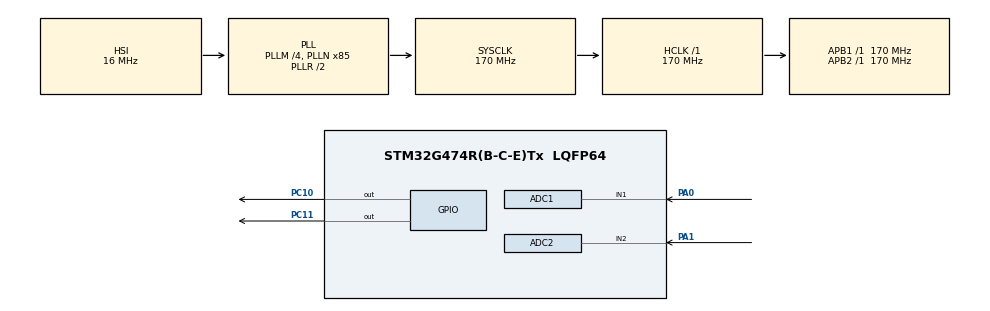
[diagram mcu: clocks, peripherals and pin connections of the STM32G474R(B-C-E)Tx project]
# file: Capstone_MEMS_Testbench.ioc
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ADC1.Channel-3\#ChannelRegularConversion=ADC_CHANNEL_1
ADC1.DMAAccessModeView=ENABLE
ADC1.DMAContinuousRequests=ENABLE
ADC1.ExternalTrigConv=ADC_EXTERNALTRIG_T6_TRGO
ADC1.Mode=ADC_DUALMODE_REGSIMULT
ADC1.NbrOfConversionFlag=1
ADC1.OffsetNumber-3\#ChannelRegularConversion=ADC_OFFSET_NONE
ADC1.Rank-3\#ChannelRegularConversion=1
ADC1.SamplingTime-3\#ChannelRegularConversion=ADC_SAMPLETIME_12CYCLES_5
ADC1.master=1
ADC2.Channel-0\#ChannelRegularConversion=ADC_CHANNEL_2
ADC2.DMAAccessModeView=ENABLE
ADC2.Mode=ADC_DUALMODE_REGSIMULT
ADC2.NbrOfConversionFlag=1
ADC2.OffsetNumber-0\#ChannelRegularConversion=ADC_OFFSET_NONE
ADC2.Rank-0\#ChannelRegularConversion=1
ADC2.SamplingTime-0\#ChannelRegularConversion=ADC_SAMPLETIME_12CYCLES_5
Dma.ADC1.0.Direction=DMA_PERIPH_TO_MEMORY
Dma.ADC1.0.EventEnable=DISABLE
Dma.ADC1.0.Instance=DMA1_Channel1
Dma.ADC1.0.MemDataAlignment=DMA_MDATAALIGN_WORD
Dma.ADC1.0.MemInc=DMA_MINC_ENABLE
Dma.ADC1.0.Mode=DMA_CIRCULAR
Dma.ADC1.0.PeriphDataAlignment=DMA_PDATAALIGN_WORD
Dma.ADC1.0.PeriphInc=DMA_PINC_DISABLE
Dma.ADC1.0.Polarity=HAL_DMAMUX_REQ_GEN_RISING
Dma.ADC1.0.Priority=DMA_PRIORITY_VERY_HIGH
Dma.ADC1.0.RequestNumber=1
Dma.ADC1.0.SignalID=NONE
Dma.ADC1.0.SyncEnable=DISABLE
Dma.ADC1.0.SyncPolarity=HAL_DMAMUX_SYNC_NO_EVENT
Dma.ADC1.0.SyncRequestNumber=1
Dma.ADC1.0.SyncSignalID=NONE
Dma.Request0=ADC1
Mcu.Family=STM32G4
Mcu.Name=STM32G474R(B-C-E)Tx
Mcu.Package=LQFP64
NUCLEO-G474RE.BUTTON=1
NUCLEO-G474RE.Bsp_Common_DEMO=true
NUCLEO-G474RE.LD2=true
NUCLEO-G474RE.VCP=true
NVIC.DMA1_Channel1_IRQn=true\:0\:0\:false\:false\:true\:false\:true\:true
NVIC.EXTI15_10_IRQn=true\:0\:0\:false\:false\:true\:false\:true\:true
NVIC.PriorityGroup=NVIC_PRIORITYGROUP_4
PA0.Mode=IN1-Single-Ended
PA0.Signal=ADC1_IN1
PA1.Mode=IN2-Single-Ended
PA1.Signal=ADC2_IN2
PA13.GPIO_Label=T_SWDIO
PA13.Signal=SYS_JTMS-SWDIO
PA14.GPIO_Label=T_SWCLK
PA14.Signal=SYS_JTCK-SWCLK
PA2.Signal=LPUART1_TX
PA3.Signal=LPUART1_RX
PB3.GPIO_Label=T_SWO
PB3.Signal=SYS_JTDO-SWO
PC10.Signal=GPIO_Output
PC11.Signal=GPIO_Output
PC14-OSC32_IN.GPIO_Label=RCC_OSC32_IN
PC14-OSC32_IN.Signal=RCC_OSC32_IN
PC15-OSC32_OUT.GPIO_Label=RCC_OSC32_OUT
PC15-OSC32_OUT.Signal=RCC_OSC32_OUT
PF0-OSC_IN.GPIO_Label=RCC_OSC_IN
PF0-OSC_IN.Signal=RCC_OSC_IN
PF1-OSC_OUT.GPIO_Label=RCC_OSC_OUT
PF1-OSC_OUT.Signal=RCC_OSC_OUT
ProjectManager.HeapSize=0x200
ProjectManager.StackSize=0x400
ProjectManager.TargetToolchain=CMake
RCC.ADC12Freq_Value=170000000
RCC.ADC345Freq_Value=170000000
RCC.AHBFreq_Value=170000000
RCC.APB1Freq_Value=170000000
RCC.APB1TimFreq_Value=170000000
RCC.APB2Freq_Value=170000000
RCC.APB2TimFreq_Value=170000000
RCC.CortexFreq_Value=170000000
RCC.EXTERNAL_CLOCK_VALUE=12288000
RCC.HCLKFreq_Value=170000000
RCC.HSE_VALUE=24000000
RCC.HSI48_VALUE=48000000
RCC.HSI_VALUE=16000000
RCC.LSE_VALUE=32768
RCC.PLLM=RCC_PLLM_DIV4
RCC.PLLN=85
RCC.RTCClockSelection=RCC_RTCCLKSOURCE_LSE
RCC.SYSCLKFreq_VALUE=170000000
RCC.SYSCLKSource=RCC_SYSCLKSOURCE_PLLCLK
RCC.USBFreq_Value=170000000
RCC.VCOOutputFreq_Value=340000000
TIM6.PeriodNoDither=0
TIM6.Prescaler=169
TIM6.TIM_MasterOutputTrigger=TIM_TRGO_UPDATE
VP_NUCLEO-G474RE_VS_BSP_COMMON.Mode=COMMON
VP_SYS_VS_DBSignals.Mode=DisableDeadBatterySignals
VP_TIM6_VS_ClockSourceINT.Mode=Enable_Timer
board=NUCLEO-G474RE

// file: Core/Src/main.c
/* USER CODE BEGIN Header */
/**
  ******************************************************************************
  * @file           : main.c
  * @brief          : Main program body
  ******************************************************************************
  * @attention
  *
  * Copyright (c) 2026 STMicroelectronics.
  * All rights reserved.
  *
  * This software is licensed under terms that can be found in the LICENSE file
  * in the root directory of this software component.
  * If no LICENSE file comes with this software, it is provided AS-IS.
  *
  ******************************************************************************
  */
/* USER CODE END Header */
#include "main.h"
#include "stm32g4xx_hal.h"

COM_InitTypeDef BspCOMInit;
__IO uint32_t BspButtonState = BUTTON_RELEASED;
ADC_HandleTypeDef hadc1;
ADC_HandleTypeDef hadc2;
DMA_HandleTypeDef hdma_adc1;

TIM_HandleTypeDef htim6;

void SystemClock_Config(void);
static void MX_GPIO_Init(void);
static void MX_DMA_Init(void);
static void MX_TIM6_Init(void);
static void MX_ADC1_Init(void);
static void MX_ADC2_Init(void);

int main(void)
{

  /* MCU Configuration--------------------------------------------------------*/

  /* Reset of all peripherals, Initializes the Flash interface and the Systick. */
  HAL_Init();

  /* Configure the system clock */
  SystemClock_Config();

  /* Initialize all configured peripherals */
  MX_GPIO_Init();
  MX_DMA_Init();
  MX_TIM6_Init();
  MX_ADC1_Init();
  MX_ADC2_Init();

  /* Initialize led */
  BSP_LED_Init(LED_GREEN);

  /* Initialize USER push-button, will be used to trigger an interrupt each time it's pressed.*/
  BSP_PB_Init(BUTTON_USER, BUTTON_MODE_EXTI);

  /* Initialize COM1 port (115200, 8 bits (7-bit data + 1 stop bit), no parity */
  BspCOMInit.BaudRate   = 115200;
  BspCOMInit.WordLength = COM_WORDLENGTH_8B;
  BspCOMInit.StopBits   = COM_STOPBITS_1;
  BspCOMInit.Parity     = COM_PARITY_NONE;
  BspCOMInit.HwFlowCtl  = COM_HWCONTROL_NONE;
  if (BSP_COM_Init(COM1, &BspCOMInit) != BSP_ERROR_NONE)
  {
    Error_Handler();
  }

  /* USER CODE BEGIN BSP */

  /* -- Sample board code to send message over COM1 port ---- */
  printf("Welcome to STM32 world !\n\r");

  /* -- Sample board code to switch on led ---- */
  BSP_LED_On(LED_GREEN);

  /* USER CODE END BSP */

  /* Infinite loop */
  /* USER CODE BEGIN WHILE */
  while (1)
  {

    /* -- Sample board code for User push-button in interrupt mode ---- */
    if (BspButtonState == BUTTON_PRESSED)
    {
      /* Update button state */
      BspButtonState = BUTTON_RELEASED;
      /* -- Sample board code to toggle led ---- */
      BSP_LED_Toggle(LED_GREEN);
      // HAL_Delay(500); /* Delay of 100ms */
      /* ..... Perform your action ..... */
    }
    /* USER CODE END WHILE */

  }
}

void SystemClock_Config(void)
{
  RCC_OscInitTypeDef RCC_OscInitStruct = {0};
  RCC_ClkInitTypeDef RCC_ClkInitStruct = {0};

  /** Configure the main internal regulator output voltage
  */
  HAL_PWREx_ControlVoltageScaling(PWR_REGULATOR_VOLTAGE_SCALE1_BOOST);

  /** Initializes the RCC Oscillators according to the specified parameters
  * in the RCC_OscInitTypeDef structure.
  */
  RCC_OscInitStruct.OscillatorType = RCC_OSCILLATORTYPE_HSI;
  RCC_OscInitStruct.HSIState = RCC_HSI_ON;
  RCC_OscInitStruct.HSICalibrationValue = RCC_HSICALIBRATION_DEFAULT;
  RCC_OscInitStruct.PLL.PLLState = RCC_PLL_ON;
  RCC_OscInitStruct.PLL.PLLSource = RCC_PLLSOURCE_HSI;
  RCC_OscInitStruct.PLL.PLLM = RCC_PLLM_DIV4;
  RCC_OscInitStruct.PLL.PLLN = 85;
  RCC_OscInitStruct.PLL.PLLP = RCC_PLLP_DIV2;
  RCC_OscInitStruct.PLL.PLLQ = RCC_PLLQ_DIV2;
  RCC_OscInitStruct.PLL.PLLR = RCC_PLLR_DIV2;
  if (HAL_RCC_OscConfig(&RCC_OscInitStruct) != HAL_OK)
  {
    Error_Handler();
  }

  /** Initializes the CPU, AHB and APB buses clocks
  */
  RCC_ClkInitStruct.ClockType = RCC_CLOCKTYPE_HCLK|RCC_CLOCKTYPE_SYSCLK
                              |RCC_CLOCKTYPE_PCLK1|RCC_CLOCKTYPE_PCLK2;
  RCC_ClkInitStruct.SYSCLKSource = RCC_SYSCLKSOURCE_PLLCLK;
  RCC_ClkInitStruct.AHBCLKDivider = RCC_SYSCLK_DIV1;
  RCC_ClkInitStruct.APB1CLKDivider = RCC_HCLK_DIV1;
  RCC_ClkInitStruct.APB2CLKDivider = RCC_HCLK_DIV1;

  if (HAL_RCC_ClockConfig(&RCC_ClkInitStruct, FLASH_LATENCY_4) != HAL_OK)
  {
    Error_Handler();
  }
}

static void MX_ADC1_Init(void)
{

  ADC_MultiModeTypeDef multimode = {0};
  ADC_ChannelConfTypeDef sConfig = {0};

  /** Common config
  */
  hadc1.Instance = ADC1;
  hadc1.Init.ClockPrescaler = ADC_CLOCK_SYNC_PCLK_DIV4;
  hadc1.Init.Resolution = ADC_RESOLUTION_12B;
  hadc1.Init.DataAlign = ADC_DATAALIGN_RIGHT;
  hadc1.Init.GainCompensation = 0;
  hadc1.Init.ScanConvMode = ADC_SCAN_DISABLE;
  hadc1.Init.EOCSelection = ADC_EOC_SINGLE_CONV;
  hadc1.Init.LowPowerAutoWait = DISABLE;
  hadc1.Init.ContinuousConvMode = DISABLE;
  hadc1.Init.NbrOfConversion = 1;
  hadc1.Init.DiscontinuousConvMode = DISABLE;
  hadc1.Init.ExternalTrigConv = ADC_EXTERNALTRIG_T6_TRGO;
  hadc1.Init.ExternalTrigConvEdge = ADC_EXTERNALTRIGCONVEDGE_RISING;
  hadc1.Init.DMAContinuousRequests = ENABLE;
  hadc1.Init.Overrun = ADC_OVR_DATA_PRESERVED;
  hadc1.Init.OversamplingMode = DISABLE;
  if (HAL_ADC_Init(&hadc1) != HAL_OK)
  {
    Error_Handler();
  }

  /** Configure the ADC multi-mode
  */
  multimode.Mode = ADC_DUALMODE_REGSIMULT;
  multimode.DMAAccessMode = ADC_DMAACCESSMODE_12_10_BITS;
  multimode.TwoSamplingDelay = ADC_TWOSAMPLINGDELAY_1CYCLE;
  if (HAL_ADCEx_MultiModeConfigChannel(&hadc1, &multimode) != HAL_OK)
  {
    Error_Handler();
  }

  /** Configure Regular Channel
  */
  sConfig.Channel = ADC_CHANNEL_1;
  sConfig.Rank = ADC_REGULAR_RANK_1;
  sConfig.SamplingTime = ADC_SAMPLETIME_12CYCLES_5;
  sConfig.SingleDiff = ADC_SINGLE_ENDED;
  sConfig.OffsetNumber = ADC_OFFSET_NONE;
  sConfig.Offset = 0;
  if (HAL_ADC_ConfigChannel(&hadc1, &sConfig) != HAL_OK)
  {
    Error_Handler();
  }

}

static void MX_ADC2_Init(void)
{

  ADC_ChannelConfTypeDef sConfig = {0};

  /** Common config
  */
  hadc2.Instance = ADC2;
  hadc2.Init.ClockPrescaler = ADC_CLOCK_SYNC_PCLK_DIV4;
  hadc2.Init.Resolution = ADC_RESOLUTION_12B;
  hadc2.Init.DataAlign = ADC_DATAALIGN_RIGHT;
  hadc2.Init.GainCompensation = 0;
  hadc2.Init.ScanConvMode = ADC_SCAN_DISABLE;
  hadc2.Init.EOCSelection = ADC_EOC_SINGLE_CONV;
  hadc2.Init.LowPowerAutoWait = DISABLE;
  hadc2.Init.ContinuousConvMode = DISABLE;
  hadc2.Init.NbrOfConversion = 1;
  hadc2.Init.DiscontinuousConvMode = DISABLE;
  hadc2.Init.DMAContinuousRequests = DISABLE;
  hadc2.Init.Overrun = ADC_OVR_DATA_PRESERVED;
  hadc2.Init.OversamplingMode = DISABLE;
  if (HAL_ADC_Init(&hadc2) != HAL_OK)
  {
    Error_Handler();
  }

  /** Configure Regular Channel
  */
  sConfig.Channel = ADC_CHANNEL_2;
  sConfig.Rank = ADC_REGULAR_RANK_1;
  sConfig.SamplingTime = ADC_SAMPLETIME_12CYCLES_5;
  sConfig.SingleDiff = ADC_SINGLE_ENDED;
  sConfig.OffsetNumber = ADC_OFFSET_NONE;
  sConfig.Offset = 0;
  if (HAL_ADC_ConfigChannel(&hadc2, &sConfig) != HAL_OK)
  {
    Error_Handler();
  }

}

static void MX_TIM6_Init(void)
{

  TIM_MasterConfigTypeDef sMasterConfig = {0};

  htim6.Instance = TIM6;
  htim6.Init.Prescaler = 169;
  htim6.Init.CounterMode = TIM_COUNTERMODE_UP;
  htim6.Init.Period = 0;
  htim6.Init.AutoReloadPreload = TIM_AUTORELOAD_PRELOAD_DISABLE;
  if (HAL_TIM_Base_Init(&htim6) != HAL_OK)
  {
    Error_Handler();
  }
  sMasterConfig.MasterOutputTrigger = TIM_TRGO_UPDATE;
  sMasterConfig.MasterSlaveMode = TIM_MASTERSLAVEMODE_DISABLE;
  if (HAL_TIMEx_MasterConfigSynchronization(&htim6, &sMasterConfig) != HAL_OK)
  {
    Error_Handler();
  }

}

static void MX_DMA_Init(void)
{

  /* DMA controller clock enable */
  __HAL_RCC_DMAMUX1_CLK_ENABLE();
  __HAL_RCC_DMA1_CLK_ENABLE();

  /* DMA interrupt init */
  /* DMA1_Channel1_IRQn interrupt configuration */
  HAL_NVIC_SetPriority(DMA1_Channel1_IRQn, 0, 0);
  HAL_NVIC_EnableIRQ(DMA1_Channel1_IRQn);

}

static void MX_GPIO_Init(void)
{
  GPIO_InitTypeDef GPIO_InitStruct = {0};

  /* GPIO Ports Clock Enable */
  __HAL_RCC_GPIOC_CLK_ENABLE();
  __HAL_RCC_GPIOF_CLK_ENABLE();
  __HAL_RCC_GPIOA_CLK_ENABLE();
  __HAL_RCC_GPIOB_CLK_ENABLE();

  /*Configure GPIO pin Output Level */
  HAL_GPIO_WritePin(GPIOC, GPIO_PIN_10|GPIO_PIN_11, GPIO_PIN_RESET);

  /*Configure GPIO pins : PC10 PC11 */
  GPIO_InitStruct.Pin = GPIO_PIN_10|GPIO_PIN_11;
  GPIO_InitStruct.Mode = GPIO_MODE_OUTPUT_PP;
  GPIO_InitStruct.Pull = GPIO_NOPULL;
  GPIO_InitStruct.Speed = GPIO_SPEED_FREQ_LOW;
  HAL_GPIO_Init(GPIOC, &GPIO_InitStruct);

}

/**
  * @brief BSP Push Button callback
  * @param Button Specifies the pressed button
  * @retval None
  */
void BSP_PB_Callback(Button_TypeDef Button)
{
  if (Button == BUTTON_USER)
  {
    BspButtonState = BUTTON_PRESSED;
  }
}

void Error_Handler(void)
{
  __disable_irq();
  while (1)
  {
  }
}
